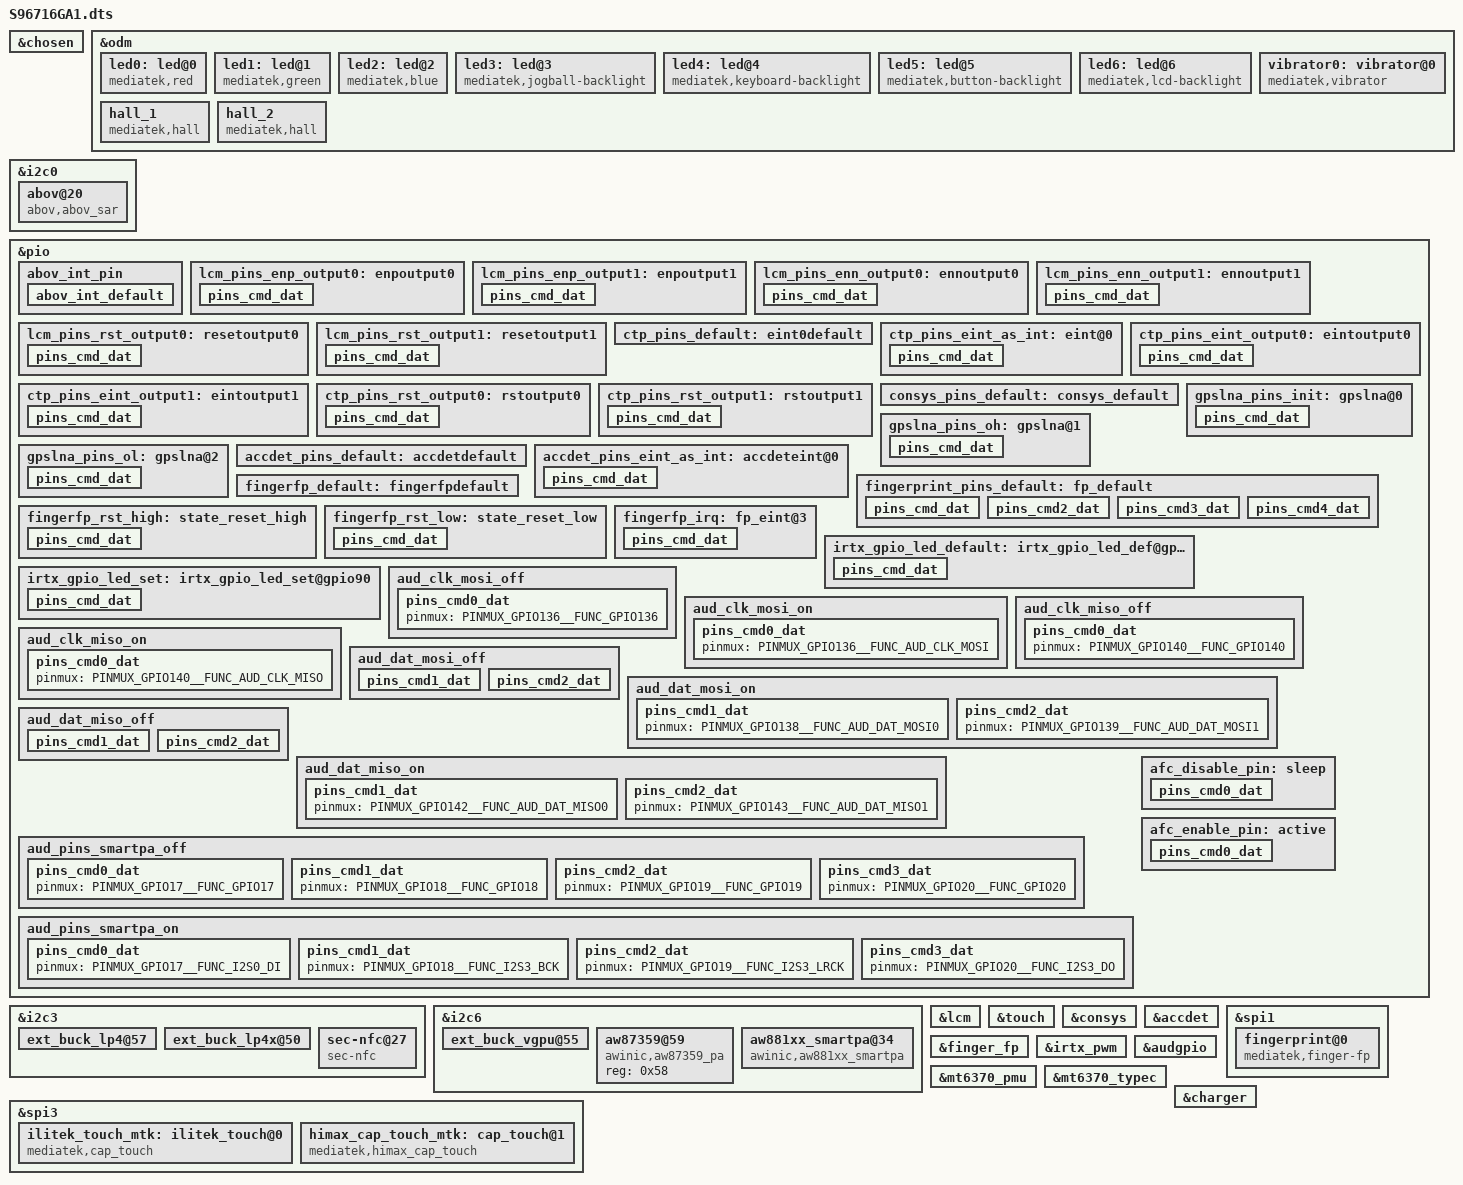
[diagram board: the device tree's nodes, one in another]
/*
 * Copyright (C) 2019 MediaTek Inc.
 *
 * This program is free software; you can redistribute it and/or modify
 * it under the terms of the GNU General Public License version 2 as
 * published by the Free Software Foundation.
 *
 * This program is distributed in the hope that it will be useful,
 * but WITHOUT ANY WARRANTY; without even the implied warranty of
 * MERCHANTABILITY or FITNESS FOR A PARTICULAR PURPOSE.
 * See http://www.gnu.org/licenses/gpl-2.0.html for more details.
 */

#include <dt-bindings/interrupt-controller/arm-gic.h>
#include <dt-bindings/interrupt-controller/irq.h>
#include <dt-bindings/pinctrl/mt6765-pinfunc.h>
#include <dt-bindings/clock/mt6765-clk.h>

/dts-v1/;
/plugin/;

/* chosen */
&chosen {

	/* fpga may has no lk, we need to specify display info here */
	/* fb buffer is reserved using this dts by memory node above */
	atag,videolfb-fb_base_h = <0x0>;
	atag,videolfb-fb_base_l = <0x5e605000>;
	atag,videolfb-islcmfound = <1>;
	/* because no lk, so lcm is not inited */
	atag,videolfb-islcm_inited = <0>;
	atag,videolfb-fps= <6000>;
	atag,videolfb-vramSize= <0x017bb000>;
	atag,videolfb-lcmname= "nt35695B_fhd_dsi_cmd_auo_rt5081_drv";
};

&odm {
	led0:led@0 {
		compatible = "mediatek,red";
		led_mode = <0>;
		data = <1>;
		pwm_config = <0 0 0 0 0>;
	};
	led1:led@1 {
		compatible = "mediatek,green";
		led_mode = <0>;
		data = <1>;
		pwm_config = <0 0 0 0 0>;
	};
	led2:led@2 {
		compatible = "mediatek,blue";
		led_mode = <0>;
		data = <1>;
		pwm_config = <0 0 0 0 0>;
	};
	led3:led@3 {
		compatible = "mediatek,jogball-backlight";
		led_mode = <0>;
		data = <1>;
		pwm_config = <0 0 0 0 0>;
	};
	led4:led@4 {
		compatible = "mediatek,keyboard-backlight";
		led_mode = <0>;
		data = <1>;
		pwm_config = <0 0 0 0 0>;
	};
	led5:led@5 {
		compatible = "mediatek,button-backlight";
		led_mode = <0>;
		data = <1>;
		pwm_config = <0 0 0 0 0>;
	};
	led6:led@6 {
		compatible = "mediatek,lcd-backlight";
		led_mode = <4>;
		data = <1>;
		pwm_config = <0 3 0 0 0>;
	};
	vibrator0:vibrator@0 {
		compatible = "mediatek,vibrator";
		vib_timer = <25>;
		vib_limit = <9>;
		vib_vol= <9>;
	};
	hall_1:hall_1{
		compatible = "mediatek,hall";
	};
	hall_2:hall_2{
		compatible = "mediatek,hall";
	};
};

&i2c0 {
    abov@20 {
        label = "AbovCapSense";
        compatible = "abov,abov_sar";
        reg = <0x20>;
        //cap_vdd-supply = <&pm8953_l10>;
        //interrupt-parent = <&tlmm>;
        //interrupts = <45 0x2008>;
        //abov,irq-gpio = <&tlmm 45 0x2008>; /* IRQ */
        interrupt-parent = <&pio>;
        interrupts = <16 IRQ_TYPE_EDGE_FALLING 16 0>;
        abov,irq-gpio = <&pio 16 0>;
        pinctrl-names = "abov_int_default";
        pinctrl-0 = <&abov_int_default>;
        cap,use_channel = <0x0f>;
        //cap,use_channel_top = <0x01>;
        //cap,use_channel_bottom = <0x00>;
        cap,use_channel_ch0 = <0x00>;
        cap,use_channel_ch1 = <0x01>;
        cap,use_channel_ch2 = <0x02>;
        cap,scan_period = <0x02>;
        //reg_array_len = <2>;
        //reg_array_val = <0x18 0x5a 0x19 0x93>;
    };
};

&pio {
    abov_int_pin {
        abov_int_default: abov_int_default {
            /* active state */
            pinmux = <PINMUX_GPIO16__FUNC_GPIO16>;
            slew-rate = <2>;
            bias-pull-up;
        };
    };
};

&i2c3 {
	ext_buck_lp4@57 {
		regulator-name ="ext_buck_vdd2";
		regulator-min-microvolt = <300000>;
		regulator-max-microvolt = <1300000>;
		vsel_pin = <0>;
	};

	ext_buck_lp4x@50 {
		regulator-name ="ext_buck_vddq";
		regulator-min-microvolt = <300000>;
		regulator-max-microvolt = <1300000>;
		vsel_pin = <1>;
	};

    sec-nfc@27 {
        compatible = "sec-nfc";
        reg = <0x27>;
        status = "okay";
        sec-nfc,ven-gpio_num = <176>; /*direct defined GPIO num */
        sec-nfc,ven-gpio = <&pio 176 0x0>;/*gpio_176*/
        sec-nfc,firm-gpio_num = <172>;
        sec-nfc,firm-gpio = <&pio 172 0x0>;/*gpio_172*/
        sec-nfc,irq-gpio_num = <10>;
        sec-nfc,irq-gpio = <&pio 10 0x0>;/*gpio_10*/
        sec-nfc,clk_req-gpio_num = <89>;
        sec-nfc,clk_req-gpio = <&pio 89 0x0>;/*gpio_89*/
    };

};

&i2c6 {
	ext_buck_vgpu@55 {
		regulator-name ="ext_buck_vgpu";
		regulator-min-microvolt = <300000>;
		regulator-max-microvolt = <1300000>;
		vsel_pin = <2>;
	};
    aw87359@59 {
        compatible = "awinic,aw87359_pa";
        reg = <0x58>;
        status = "okay";
    };
	aw881xx_smartpa@34 {
		compatible = "awinic,aw881xx_smartpa";
		reg = <0x34>;
		reset-gpio = <&pio 167 0>;
		irq-gpio = <&pio 15 0>;
		monitor-flag = <1>;
		monitor-timer-val = <30000>;
		status = "okay";
	};
};

/*LCM start*/
&lcm {
	pinctrl-names = "state_enp_output0", "state_enp_output1",
			"state_enn_output0", "state_enn_output1",
			"state_reset_output0", "state_reset_output1";
	pinctrl-0 = <&lcm_pins_enp_output0>;
	pinctrl-1 = <&lcm_pins_enp_output1>;
	pinctrl-2 = <&lcm_pins_enn_output0>;
	pinctrl-3 = <&lcm_pins_enn_output1>;
	pinctrl-4 = <&lcm_pins_rst_output0>;
	pinctrl-5 = <&lcm_pins_rst_output1>;
	status = "okay";
};
&pio {
	lcm_pins_enp_output0: enpoutput0 {
		pins_cmd_dat {
			pinmux = <PINMUX_GPIO150__FUNC_GPIO150>;
			slew-rate = <1>;
			output-low;
		};
	};
	lcm_pins_enp_output1: enpoutput1 {
		pins_cmd_dat {
			pinmux = <PINMUX_GPIO150__FUNC_GPIO150>;
			slew-rate = <1>;
			output-high;
		};
	};
	lcm_pins_enn_output0: ennoutput0 {
		pins_cmd_dat {
			pinmux = <PINMUX_GPIO151__FUNC_GPIO151>;
			slew-rate = <1>;
			output-low;
		};
	};
	lcm_pins_enn_output1: ennoutput1 {
		pins_cmd_dat {
			pinmux = <PINMUX_GPIO151__FUNC_GPIO151>;
			slew-rate = <1>;
			output-high;
		};
	};
	lcm_pins_rst_output0: resetoutput0 {
		pins_cmd_dat {
			pinmux = <PINMUX_GPIO45__FUNC_GPIO45>;
			slew-rate = <1>;
			output-low;
		};
	};
	lcm_pins_rst_output1: resetoutput1 {
		pins_cmd_dat {
			pinmux = <PINMUX_GPIO45__FUNC_GPIO45>;
			slew-rate = <1>;
			output-high;
		};
	};
};
/*LCM end*/

/* TOUCH start */
&spi3 {
	#address-cells = <1>;
	#size-cells = <0>;

	ilitek_touch_mtk:ilitek_touch@0{
		compatible = "mediatek,cap_touch","mediatek,ilitek_cap_touch";
 		spi-max-frequency = <10000000>;
		reg = <0x0>;
		status = "okay";
	};

	himax_cap_touch_mtk:cap_touch@1{
                compatible = "mediatek,himax_cap_touch";
                spi-max-frequency = <10000000>;
		reg = <0x1>;
                status = "okay";
	};
};

&touch {
	tpd-resolution = <720 1600>;
	use-tpd-button = <0>;
	tpd-key-num = <3>;
	tpd-key-local= <139 172 158 0>;
	tpd-key-dim-local = <90 883 100 40 230
				 883 100 40 370 883 100 40 0 0 0 0>;
	tpd-max-touch-num = <10>;
	tpd-filter-enable = <0>;
	tpd-filter-pixel-density = <146>;
	tpd-filter-custom-prameters = <0 0 0 0 0 0 0 0 0 0 0 0>;
	tpd-filter-custom-speed = <0 0 0>;
	pinctrl-names = "default", "state_eint_as_int", "state_eint_output0",
		"state_eint_output1", "state_rst_output0", "state_rst_output1";
	pinctrl-0 = <&ctp_pins_default>;
	pinctrl-1 = <&ctp_pins_eint_as_int>;
	pinctrl-2 = <&ctp_pins_eint_output0>;
	pinctrl-3 = <&ctp_pins_eint_output1>;
	pinctrl-4 = <&ctp_pins_rst_output0>;
	pinctrl-5 = <&ctp_pins_rst_output1>;
	status = "okay";
};
&pio {
	ctp_pins_default: eint0default {
	};
	ctp_pins_eint_as_int: eint@0 {
		pins_cmd_dat {
			pinmux = <PINMUX_GPIO0__FUNC_GPIO0>;
			slew-rate = <0>;
			bias-disable;
		};
	};
	ctp_pins_eint_output0: eintoutput0 {
		pins_cmd_dat {
			pinmux = <PINMUX_GPIO0__FUNC_GPIO0>;
			slew-rate = <1>;
			output-low;
		};
	};
	ctp_pins_eint_output1: eintoutput1 {
		pins_cmd_dat {
			pinmux = <PINMUX_GPIO0__FUNC_GPIO0>;
			slew-rate = <1>;
			output-high;
		};
	};
	ctp_pins_rst_output0: rstoutput0 {
		pins_cmd_dat {
			pinmux = <PINMUX_GPIO164__FUNC_GPIO164>;
			slew-rate = <1>;
			output-low;
		};
	};
	ctp_pins_rst_output1: rstoutput1 {
		pins_cmd_dat {
			pinmux = <PINMUX_GPIO164__FUNC_GPIO164>;
			slew-rate = <1>;
			output-high;
		};
	};
};
/* TOUCH end */

/* CONSYS GPIO standardization */
&pio {
	consys_pins_default: consys_default {
	};
	gpslna_pins_init: gpslna@0 {
		pins_cmd_dat {
			pinmux = <PINMUX_GPIO91__FUNC_GPIO91>;
			slew-rate = <0>;
			bias-disable;
			output-low;
		};
	};
	gpslna_pins_oh: gpslna@1 {
		pins_cmd_dat {
			pinmux = <PINMUX_GPIO91__FUNC_GPIO91>;
			slew-rate = <1>;
			output-high;
		};
	};
	gpslna_pins_ol: gpslna@2 {
		pins_cmd_dat {
			pinmux = <PINMUX_GPIO91__FUNC_GPIO91>;
			slew-rate = <1>;
			output-low;
		};
	};
};
&consys {
	pinctrl-names = "default", "gps_lna_state_init",
		"gps_lna_state_oh", "gps_lna_state_ol";
	pinctrl-0 = <&consys_pins_default>;
	pinctrl-1 = <&gpslna_pins_init>;
	pinctrl-2 = <&gpslna_pins_oh>;
	pinctrl-3 = <&gpslna_pins_ol>;
	status = "okay";
};
/* CONSYS end */

/* accdet start */
&accdet {
	accdet-mic-vol = <6>;
	headset-mode-setting = <0x500 0x500 1 0x1f0 0x800 0x800 0x20 0x44>;
	accdet-plugout-debounce = <1>;
	accdet-mic-mode = <1>;
	headset-eint-level-pol = <8>;
	headset-three-key-threshold = <0 80 220 400>;
	headset-three-key-threshold-CDD = <0 121 192 600>;
	headset-four-key-threshold = <0 58 121 192 400>;
	pinctrl-names = "default", "state_eint_as_int";
	pinctrl-0 = <&accdet_pins_default>;
	pinctrl-1 = <&accdet_pins_eint_as_int>;
	status = "okay";
};
&pio {
	accdet_pins_default: accdetdefault {
	};
	accdet_pins_eint_as_int: accdeteint@0 {
		pins_cmd_dat {
			pinmux = <PINMUX_GPIO9__FUNC_GPIO9>;
			slew-rate = <0>;
			bias-disable;
		};
	};
};
/* accdet end */

/* FINGERPRINT start */
&spi1 {
	#address-cells = <1>;
	#size-cells = <0>;
	fingerprint@0 {
		compatible = "mediatek,finger-fp";
		reg = <0>;
		spi-max-frequency = <8000000>;
		netlink-event = <30>;
		status = "okay";
	};
};

&finger_fp {
	int-gpios = <&pio 14 0>;
	pinctrl-names = "default", "rst-low", "rst-high" ,
	                "irq-init", "spi-default";
	pinctrl-0 = <&fingerfp_default>;
	pinctrl-1 = <&fingerfp_rst_low>;
	pinctrl-2 = <&fingerfp_rst_high>;
	pinctrl-3 = <&fingerfp_irq>;
	pinctrl-4 = <&fingerprint_pins_default>;
	status = "okay";
};



&pio {
	fingerprint_pins_default: fp_default {
		pins_cmd_dat {
			pinmux = <PINMUX_GPIO26__FUNC_SPI1_A_CSB>;
			slew-rate = <1>;
			bias-pull-up;
		};

		pins_cmd2_dat {
			pinmux = <PINMUX_GPIO28__FUNC_SPI1_A_CLK>;
			slew-rate = <1>;
			bias-pull-down;
		};

		pins_cmd3_dat {
			pinmux = <PINMUX_GPIO25__FUNC_SPI1_A_MI>;
			slew-rate = <0>;
			bias-pull-down;
		};

		pins_cmd4_dat {
			pinmux = <PINMUX_GPIO27__FUNC_SPI1_A_MO>;
			slew-rate = <1>;
			bias-pull-down;
		};
	};

	fingerfp_default: fingerfpdefault {
	};

	fingerfp_rst_high: state_reset_high {
		pins_cmd_dat {
			pinmux = <PINMUX_GPIO170__FUNC_GPIO170>;
			slew-rate = <1>;
			output-high;
		};
	};

	fingerfp_rst_low: state_reset_low {
		pins_cmd_dat {
			pinmux = <PINMUX_GPIO170__FUNC_GPIO170>;
			slew-rate = <1>;
			output-low;
		};
	};

	fingerfp_irq: fp_eint@3 {
		pins_cmd_dat {
			pinmux = <PINMUX_GPIO3__FUNC_GPIO3>;
			slew-rate = <0>;
			bias-disable;
		};
	};

};
/* FINGERPRINT end */

/* IRTX GPIO end */
&irtx_pwm {
	pinctrl-names = "irtx_gpio_led_default", "irtx_gpio_led_set";
	pinctrl-0 = <&irtx_gpio_led_default>;
	pinctrl-1 = <&irtx_gpio_led_set>;
	status = "okay";
};
&pio {
	irtx_gpio_led_default:irtx_gpio_led_def@gpio90 {
		pins_cmd_dat {
			pinmux = <PINMUX_GPIO90__FUNC_GPIO90>;
			slew-rate = <1>;
			bias-disable;
			output-low;
			input-schmitt-enable = <0>;
		};
	};

	irtx_gpio_led_set:irtx_gpio_led_set@gpio90 {
		pins_cmd_dat {
			pinmux = <PINMUX_GPIO90__FUNC_PWM0>;
			slew-rate = <1>;
			output-high;
		};
	};
};
/* IRTX GPIO Settings -End */

/* AUDIO GPIO standardization */
&audgpio {
	pinctrl-names = "aud_clk_mosi_off",
			"aud_clk_mosi_on",
			"aud_clk_miso_off",
			"aud_clk_miso_on",
			"aud_dat_mosi_off",
			"aud_dat_mosi_on",
			"aud_dat_miso_off",
			"aud_dat_miso_on",
			"aud_smartpa_off",
			"aud_smartpa_on";
	pinctrl-0 = <&aud_clk_mosi_off>;
	pinctrl-1 = <&aud_clk_mosi_on>;
	pinctrl-2 = <&aud_clk_miso_off>;
	pinctrl-3 = <&aud_clk_miso_on>;
	pinctrl-4 = <&aud_dat_mosi_off>;
	pinctrl-5 = <&aud_dat_mosi_on>;
	pinctrl-6 = <&aud_dat_miso_off>;
	pinctrl-7 = <&aud_dat_miso_on>;
	pinctrl-8 = <&aud_pins_smartpa_off>;
	pinctrl-9 = <&aud_pins_smartpa_on>;
	status = "okay";
};

&pio {
	aud_clk_mosi_off: aud_clk_mosi_off {
		pins_cmd0_dat {
			pinmux = <PINMUX_GPIO136__FUNC_GPIO136>;
		};
	};

	aud_clk_mosi_on: aud_clk_mosi_on {
		pins_cmd0_dat {
			pinmux = <PINMUX_GPIO136__FUNC_AUD_CLK_MOSI>;
		};
	};

	aud_clk_miso_off: aud_clk_miso_off {
		pins_cmd0_dat {
			pinmux = <PINMUX_GPIO140__FUNC_GPIO140>;
		};
	};

	aud_clk_miso_on: aud_clk_miso_on {
		pins_cmd0_dat {
			pinmux = <PINMUX_GPIO140__FUNC_AUD_CLK_MISO>;
		};
	};

	aud_dat_mosi_off: aud_dat_mosi_off {
		pins_cmd1_dat {
			pinmux = <PINMUX_GPIO138__FUNC_GPIO138>;
			input-enable;
			slew-rate = <0>;
			bias-disable;
		};
		pins_cmd2_dat {
			pinmux = <PINMUX_GPIO139__FUNC_GPIO139>;
			input-enable;
			slew-rate = <0>;
			bias-disable;
		};
	};

	aud_dat_mosi_on: aud_dat_mosi_on {
		pins_cmd1_dat {
			pinmux = <PINMUX_GPIO138__FUNC_AUD_DAT_MOSI0>;
		};
		pins_cmd2_dat {
			pinmux = <PINMUX_GPIO139__FUNC_AUD_DAT_MOSI1>;
		};
	};

	aud_dat_miso_off: aud_dat_miso_off {
		pins_cmd1_dat {
			pinmux = <PINMUX_GPIO142__FUNC_GPIO142>;
			input-enable;
			slew-rate = <0>;
			bias-disable;
		};
		pins_cmd2_dat {
			pinmux = <PINMUX_GPIO143__FUNC_GPIO143>;
			input-enable;
			slew-rate = <0>;
			bias-disable;
		};
	};

	aud_dat_miso_on: aud_dat_miso_on {
		pins_cmd1_dat {
			pinmux = <PINMUX_GPIO142__FUNC_AUD_DAT_MISO0>;
		};
		pins_cmd2_dat {
			pinmux = <PINMUX_GPIO143__FUNC_AUD_DAT_MISO1>;
		};
	};

	aud_pins_smartpa_off: aud_pins_smartpa_off {
		pins_cmd0_dat {
			pinmux = <PINMUX_GPIO17__FUNC_GPIO17>;
		};
		pins_cmd1_dat {
			pinmux = <PINMUX_GPIO18__FUNC_GPIO18>;
		};
		pins_cmd2_dat {
			pinmux = <PINMUX_GPIO19__FUNC_GPIO19>;
		};
		pins_cmd3_dat {
			pinmux = <PINMUX_GPIO20__FUNC_GPIO20>;
		};
	};

	aud_pins_smartpa_on: aud_pins_smartpa_on {
		pins_cmd0_dat {
			pinmux = <PINMUX_GPIO17__FUNC_I2S0_DI>;
		};
		pins_cmd1_dat {
			pinmux = <PINMUX_GPIO18__FUNC_I2S3_BCK>;
		};
		pins_cmd2_dat {
			pinmux = <PINMUX_GPIO19__FUNC_I2S3_LRCK>;
		};
		pins_cmd3_dat {
			pinmux = <PINMUX_GPIO20__FUNC_I2S3_DO>;
		};
	};
};
/* AUDIO end */

&mt6370_pmu {
	mt6370,intr_gpio_num = <11>; /* direct defined GPIO num */
	mt6370,intr_gpio = <&pio 11 0x0>;
};

&mt6370_typec {
	mt6370pd,intr_gpio_num = <41>; /* direct defined GPIO num */
	mt6370pd,intr_gpio = <&pio 41 0x0>;
};


/* yuanjian.wt add for AFC */
&charger {

	pinctrl-names = "active", "sleep";
	pinctrl-0 = <&afc_enable_pin>;
	pinctrl-1 = <&afc_disable_pin>;
        status = "okay";
};

&pio {
	afc_disable_pin: sleep {
		pins_cmd0_dat {
			pinmux = <PINMUX_GPIO42__FUNC_GPIO42>;
			slew-rate = <1>;
                        input-enable;
			bias-disable;
		};
	     };

	afc_enable_pin: active {
		pins_cmd0_dat {
			pinmux = <PINMUX_GPIO42__FUNC_GPIO42>;
			slew-rate = <1>;
			bias-disable;
		};
	      };
 };

#include "S96716GA1/cust.dtsi"
#include "cust_mt6765_camera.dtsi"
/*End of this file, DO NOT ADD ANYTHING HERE*/
